# WE2_S_NS register map
Vendor: ARM Ltd.; Series: ARMv8.1-M Mainline; File version: 1.0
CPU: CM55 r1p1, little endian, MPU, FPU, double-precision FPU, DSP, VTOR, 3 interrupt priority bits
Registers are 32-bit, read-write, reset 0x0 unless marked. A register's access mark holds for its fields unless they carry their own. Offsets are from the block's base; [hi:lo] are bit positions; {n}, {i} and the like mark numbered series.

## I3C_MST
Base 0x530F0000
Same registers: I3C_MST_NS 0x430F0000
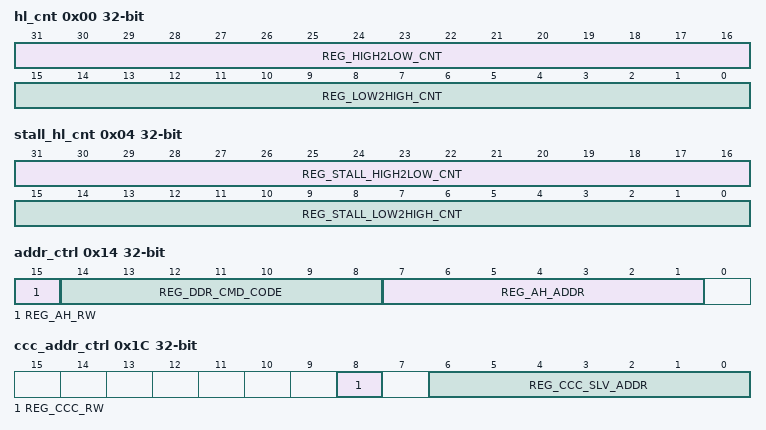
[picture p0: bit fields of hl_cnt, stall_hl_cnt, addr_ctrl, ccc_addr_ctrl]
0x00 hl_cnt — [15:0] REG_LOW2HIGH_CNT/[31:16] REG_HIGH2LOW_CNT
  [31:16] REG_HIGH2LOW_CNT, [15:0] REG_LOW2HIGH_CNT
0x04 stall_hl_cnt — [15:0] REG_STALL_LOW2HIGH_CNT/[31:16] REG_STALL_HIGH2LOW_CNT
  [31:16] REG_STALL_HIGH2LOW_CNT, [15:0] REG_STALL_LOW2HIGH_CNT
0x0C sp_sda_change_cnt — [15:0] REG_SP_SDA_CHANGE_CNT
  [15:0] REG_SP_SDA_CHANGE_CNT
0x10 protocol — [3:0] REG_PROTOCOL
  [3:0] REG_PROTOCOL
0x14 addr_ctrl — [7:1] REG_AH_ADDR/[14:8] REG_DDR_CMD_CODE/[15] REG_AH_RW
  [15] REG_AH_RW, [14:8] REG_DDR_CMD_CODE, [7:1] REG_AH_ADDR
0x18 ccc_code — [7:0] REG_CCC_CODE
  [7:0] REG_CCC_CODE
0x1C ccc_addr_ctrl — [6:0] REG_CCC_SLV_ADDR/[8] REG_CCC_RW
  [8] REG_CCC_RW, [6:0] REG_CCC_SLV_ADDR
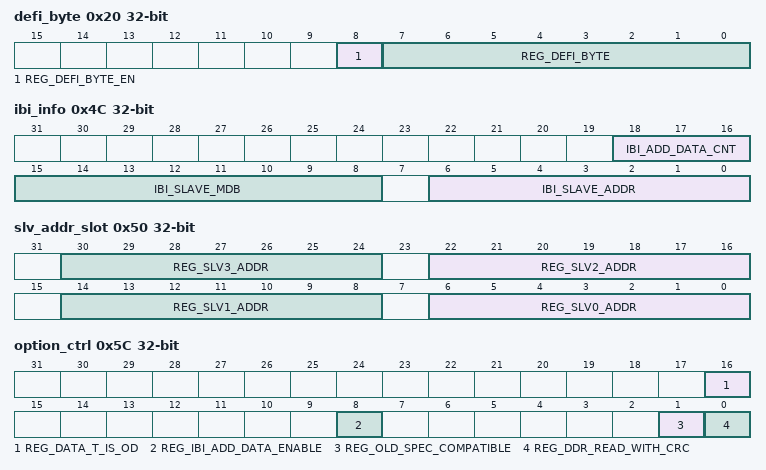
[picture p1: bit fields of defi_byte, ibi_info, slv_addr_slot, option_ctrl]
0x20 defi_byte — [7:0] REG_DEFI_BYTE/[8] REG_DEFI_BYTE_EN
  [8] REG_DEFI_BYTE_EN, [7:0] REG_DEFI_BYTE
0x24 data_length — [23:0] REG_NUMBER_OF_DATA
  [23:0] REG_NUMBER_OF_DATA
0x28 wdata — [31:0] REG_I3C_WDATA
  [31:0] REG_I3C_WDATA
0x2C rdata — [31:0] REG_I3C_RDATA
  [31:0] REG_I3C_RDATA
0x30 real_datalen_trf — [23:0] REAL_DATA_TRANSFER
  [23:0] REAL_DATA_TRANSFER
0x34 water_mark — [5:0] REG_WATER_MARK
  [5:0] REG_WATER_MARK
0x38 data_mode — [0] REG_DATA_MODE
  [0] REG_DATA_MODE
0x3C fr_start — [0] REG_I3C_FRAME_START
  [0] REG_I3C_FRAME_START
0x40 cmd_going — I3C_CMD_GOING
0x44 int_enable — [15:0] REG_I3C_HC_INT_ENABLE
  [15:0] REG_I3C_HC_INT_ENABLE
0x48 int_status — REG_I3C_HC_INT_STATUS
0x4C ibi_info — [6:0] IBI_SLAVE_ADDR/[15:8] IBI_SLAVE_MDB/[18:16] IBI_ADD_DATA_CNT
  [18:16] IBI_ADD_DATA_CNT, [15:8] IBI_SLAVE_MDB, [6:0] IBI_SLAVE_ADDR
0x50 slv_addr_slot — [6:0] REG_SLV0_ADDR/[14:8] REG_SLV1_ADDR/[22:16] REG_SLV2_ADDR/[30:24] REG_SLV3_ADDR
  [8n+6:8n] REG_SLV{n}_ADDR (n=0..3)
0x54 ibi_data — [31:0] IBI_ADD_DATA
  [31:0] IBI_ADD_DATA
0x5C option_ctrl — [0] REG_DDR_READ_WITH_CRC/[1] REG_OLD_SPEC_COMPATIBLE/[8] REG_IBI_ADD_DATA_ENABLE/[16] REG_DATA_T_IS_OD
  [16] REG_DATA_T_IS_OD, [8] REG_IBI_ADD_DATA_ENABLE, [1] REG_OLD_SPEC_COMPATIBLE, [0] REG_DDR_READ_WITH_CRC
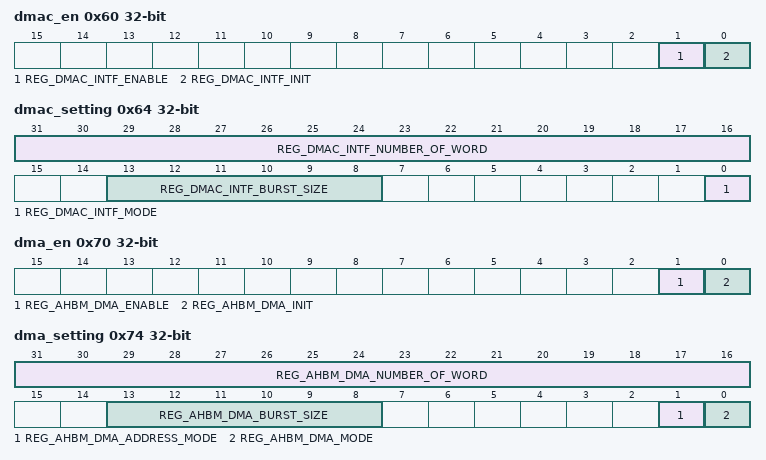
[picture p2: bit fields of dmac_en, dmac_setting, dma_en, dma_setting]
0x60 dmac_en — [0] REG_DMAC_INTF_INIT/[1] REG_DMAC_INTF_ENABLE
  [1] REG_DMAC_INTF_ENABLE, [0] REG_DMAC_INTF_INIT
0x64 dmac_setting — [0] REG_DMAC_INTF_MODE/[13:8] REG_DMAC_INTF_BURST_SIZE/[31:16] REG_DMAC_INTF_NUMBER_OF_WORD
  [31:16] REG_DMAC_INTF_NUMBER_OF_WORD, [13:8] REG_DMAC_INTF_BURST_SIZE, [0] REG_DMAC_INTF_MODE
0x68 dmac_remain_cnt — [15:0] DMAC_INTF_REMAIN_WORD_NUM
  [15:0] DMAC_INTF_REMAIN_WORD_NUM
0x70 dma_en — [0] REG_AHBM_DMA_INIT/[1] REG_AHBM_DMA_ENABLE
  [1] REG_AHBM_DMA_ENABLE, [0] REG_AHBM_DMA_INIT
0x74 dma_setting — [0] REG_AHBM_DMA_MODE/[1] REG_AHBM_DMA_ADDRESS_MODE/[13:8] REG_AHBM_DMA_BURST_SIZE/[31:16] REG_AHBM_DMA_NUMBER_OF_WORD
  [31:16] REG_AHBM_DMA_NUMBER_OF_WORD, [13:8] REG_AHBM_DMA_BURST_SIZE, [1] REG_AHBM_DMA_ADDRESS_MODE, [0] REG_AHBM_DMA_MODE
0x78 dma_remain_cnt — [15:0] AHBM_DMA_REMAIN_WORD_NUM
  [15:0] AHBM_DMA_REMAIN_WORD_NUM
0x7C dma_addr — [31:0] REG_AHBM_DMA_ADDRESS
  [31:0] REG_AHBM_DMA_ADDRESS
0x90 vout_en — [0] REG_VIDEO_OUT_EN
  [0] REG_VIDEO_OUT_EN
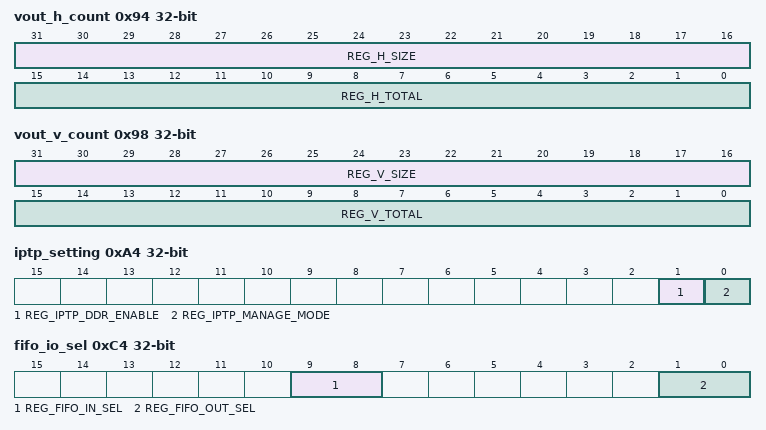
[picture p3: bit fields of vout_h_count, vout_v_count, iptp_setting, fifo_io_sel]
0x94 vout_h_count — [15:0] REG_H_TOTAL/[31:16] REG_H_SIZE
  [31:16] REG_H_SIZE, [15:0] REG_H_TOTAL
0x98 vout_v_count — [15:0] REG_V_TOTAL/[31:16] REG_V_SIZE
  [31:16] REG_V_SIZE, [15:0] REG_V_TOTAL
0x9C vout_data_width — [1:0] REG_VO_DATA_WIDTH
  [1:0] REG_VO_DATA_WIDTH
0xA0 iptp_auto_en — [0] REG_IPTP_AUTO_ENABLE
  [0] REG_IPTP_AUTO_ENABLE
0xA4 iptp_setting — [0] REG_IPTP_MANAGE_MODE/[1] REG_IPTP_DDR_ENABLE
  [1] REG_IPTP_DDR_ENABLE, [0] REG_IPTP_MANAGE_MODE
0xC0 fifo_init — [0] REG_FIFO_INITIAL
  [0] REG_FIFO_INITIAL
0xC4 fifo_io_sel — [1:0] REG_FIFO_OUT_SEL/[9:8] REG_FIFO_IN_SEL
  [9:8] REG_FIFO_IN_SEL, [1:0] REG_FIFO_OUT_SEL
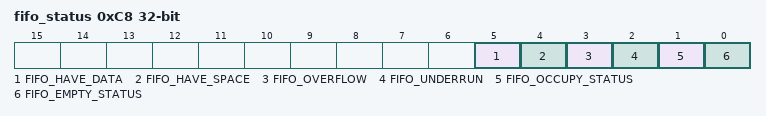
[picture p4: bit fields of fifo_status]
0xC8 fifo_status — [0] FIFO_EMPTY_STATUS/[1] FIFO_OCCUPY_STATUS/[2] FIFO_UNDERRUN/[3] FIFO_OVERFLOW/[4] FIFO_HAVE_SPACE/[5] FIFO_HAVE_DATA
  [5] FIFO_HAVE_DATA, [4] FIFO_HAVE_SPACE, [3] FIFO_OVERFLOW, [2] FIFO_UNDERRUN, [1] FIFO_OCCUPY_STATUS, [0] FIFO_EMPTY_STATUS
0xFC dbg_force_slvack — [0] REG_FORCE_SLV_ACK
  [0] REG_FORCE_SLV_ACK
0x100 fifo_port — [0] REG_FIFO_POR
  [0] REG_FIFO_POR
